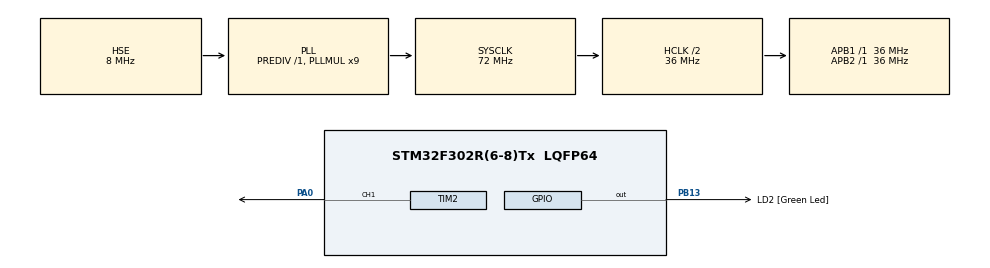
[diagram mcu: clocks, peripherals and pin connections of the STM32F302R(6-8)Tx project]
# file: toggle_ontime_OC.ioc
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Mcu.Family=STM32F3
Mcu.Name=STM32F302R(6-8)Tx
Mcu.Package=LQFP64
NVIC.PriorityGroup=NVIC_PRIORITYGROUP_0
NVIC.TIM2_IRQn=true\:0\:0\:false\:false\:true\:true\:true\:true
PA0.GPIO_ModeDefaultPP=GPIO_MODE_AF_PP
PA0.Signal=S_TIM2_CH1_ETR
PA13.GPIO_Label=TMS
PA13.Mode=Serial_Wire
PA13.Signal=SYS_JTMS-SWDIO
PA14.GPIO_Label=TCK
PA14.Mode=Serial_Wire
PA14.Signal=SYS_JTCK-SWCLK
PB13.GPIO_Label=LD2 [Green Led]
PB13.Signal=GPIO_Output
PB3.GPIO_Label=SWO
PB3.Signal=SYS_JTDO-TRACESWO
PC14\ -\ OSC32_IN.Mode=LSE-External-Clock-Source
PC14\ -\ OSC32_IN.Signal=RCC_OSC32_IN
PF0-OSC_IN.Mode=HSE-External-Oscillator
PF0-OSC_IN.Signal=RCC_OSC_IN
PF1-OSC_OUT.Mode=HSE-External-Oscillator
PF1-OSC_OUT.Signal=RCC_OSC_OUT
ProjectManager.HeapSize=0x200
ProjectManager.StackSize=0x400
ProjectManager.TargetToolchain=STM32CubeIDE
RCC.AHBCLKDivider=RCC_SYSCLK_DIV2
RCC.AHBFreq_Value=36000000
RCC.APB1Freq_Value=36000000
RCC.APB1TimFreq_Value=36000000
RCC.APB2Freq_Value=36000000
RCC.APB2TimFreq_Value=36000000
RCC.CortexFreq_Value=36000000
RCC.HCLKFreq_Value=36000000
RCC.HSE_VALUE=8000000
RCC.HSI_VALUE=8000000
RCC.LSE_VALUE=32768
RCC.PLLM=8
RCC.PLLMUL=RCC_PLL_MUL9
RCC.PLLN=336
RCC.PLLP=RCC_PLLP_DIV4
RCC.PLLQ=7
RCC.PLLSourceVirtual=RCC_PLLSOURCE_HSE
RCC.SYSCLKFreq_VALUE=72000000
RCC.SYSCLKSourceVirtual=RCC_SYSCLKSOURCE_PLLCLK
RCC.USBFreq_Value=72000000
SH.S_TIM2_CH1_ETR.0=TIM2_CH1,Output Compare1 CH1
TIM2.AutoReloadPreload=TIM_AUTORELOAD_PRELOAD_ENABLE
TIM2.Channel-Output\ Compare1\ CH1=TIM_CHANNEL_1
TIM2.OCMode_1=TIM_OCMODE_TOGGLE
TIM2.Period=65535
TIM2.Prescaler=71
TIM2.Pulse-Output\ Compare1\ CH1=1000
VP_TIM2_VS_ClockSourceINT.Mode=Internal
board=NUCLEO-F302R8

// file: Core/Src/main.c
/* USER CODE BEGIN Header */
/**
  ******************************************************************************
  * @file           : main.c
  * @brief          : Main program body
  ******************************************************************************
  * @attention
  *
  * Copyright (c) 2026 STMicroelectronics.
  * All rights reserved.
  *
  * This software is licensed under terms that can be found in the LICENSE file
  * in the root directory of this software component.
  * If no LICENSE file comes with this software, it is provided AS-IS.
  *
  ******************************************************************************
  */
/* USER CODE END Header */
#include "main.h"
#include "tim.h"
#include "gpio.h"

/* USER CODE BEGIN PV */

//uint8_t rise = 0;
//uint8_t fall = 0;
//uint8_t on_Time = 0;
//uint8_t state = 0;
//uint8_t ontime_us = 0;

/* USER CODE END PV */

void SystemClock_Config(void);

int main(void)
{

  /* MCU Configuration--------------------------------------------------------*/

  /* Reset of all peripherals, Initializes the Flash interface and the Systick. */
  HAL_Init();

  /* Configure the system clock */
  SystemClock_Config();

  /* Initialize all configured peripherals */
  MX_GPIO_Init();
  MX_TIM2_Init();
  /* USER CODE BEGIN 2 */
  HAL_TIM_OC_Start_IT(&htim2, TIM_CHANNEL_1);

  /* USER CODE END 2 */

  /* Infinite loop */
  while (1)
  {

  }
}

void SystemClock_Config(void)
{
  RCC_OscInitTypeDef RCC_OscInitStruct = {0};
  RCC_ClkInitTypeDef RCC_ClkInitStruct = {0};

  /** Initializes the RCC Oscillators according to the specified parameters
  * in the RCC_OscInitTypeDef structure.
  */
  RCC_OscInitStruct.OscillatorType = RCC_OSCILLATORTYPE_HSE;
  RCC_OscInitStruct.HSEState = RCC_HSE_ON;
  RCC_OscInitStruct.HSEPredivValue = RCC_HSE_PREDIV_DIV1;
  RCC_OscInitStruct.HSIState = RCC_HSI_ON;
  RCC_OscInitStruct.PLL.PLLState = RCC_PLL_ON;
  RCC_OscInitStruct.PLL.PLLSource = RCC_PLLSOURCE_HSE;
  RCC_OscInitStruct.PLL.PLLMUL = RCC_PLL_MUL9;
  if (HAL_RCC_OscConfig(&RCC_OscInitStruct) != HAL_OK)
  {
    Error_Handler();
  }

  /** Initializes the CPU, AHB and APB buses clocks
  */
  RCC_ClkInitStruct.ClockType = RCC_CLOCKTYPE_HCLK|RCC_CLOCKTYPE_SYSCLK
                              |RCC_CLOCKTYPE_PCLK1|RCC_CLOCKTYPE_PCLK2;
  RCC_ClkInitStruct.SYSCLKSource = RCC_SYSCLKSOURCE_PLLCLK;
  RCC_ClkInitStruct.AHBCLKDivider = RCC_SYSCLK_DIV2;
  RCC_ClkInitStruct.APB1CLKDivider = RCC_HCLK_DIV1;
  RCC_ClkInitStruct.APB2CLKDivider = RCC_HCLK_DIV1;

  if (HAL_RCC_ClockConfig(&RCC_ClkInitStruct, FLASH_LATENCY_1) != HAL_OK)
  {
    Error_Handler();
  }
}

/* USER CODE BEGIN 4

void HAL_TIM_OC_DelayElapsedCallback(TIM_HandleTypeDef *htim)
{
	if(state == 0)
	{
		rise = __HALTIM_GET_COUNTER(htim);
		HAL_TIM_SET_COMPARE(htim,TIM_CHANNEL_1, rise + 1500);

		state = 1;
	}
	else
	{
		fall = __HAL_TIM_GET_COUNTER(htim);
		on_Time = fall - rise ;
		ontime_us = on_Time * 2;
		HAL_TIM_SET_COMPARE(htim, TIM_CHANNEL_1, fall + 1000);

		state = 0;
	}
}

USER CODE END 4 */

void Error_Handler(void)
{
  __disable_irq();
  while (1)
  {
  }
}
